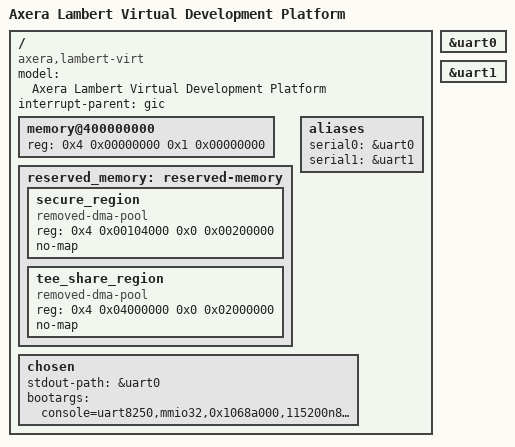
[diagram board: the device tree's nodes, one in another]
// SPDX-License-Identifier: (GPL-2.0+ OR MIT)
/*
 * Copyright (C) 2023 Axera Technology Co., Ltd
 *
 */
/dts-v1/;
#include "axera-lambert.dtsi"

/ {
	compatible = "axera,lambert-virt";
	model = "Axera Lambert Virtual Development Platform";
	#address-cells = <2>;
	#size-cells = <2>;
	interrupt-parent = <&gic>;

	memory@400000000 {
		reg = <0x4 0x00000000 0x1 0x00000000>;
		device_type = "memory";
	};

	reserved_memory: reserved-memory {
		#address-cells = <2>;
		#size-cells = <2>;
		ranges;

		secure_region {
			compatible = "removed-dma-pool";
			reg = <0x4 0x00104000 0x0 0x00200000>;
			no-map;
		};

		tee_share_region {
			compatible = "removed-dma-pool";
			reg = <0x4 0x04000000 0x0 0x02000000>;
			no-map;
		};
	};

	aliases {
		serial0 = &uart0;
		serial1 = &uart1;
	};

	chosen {
		stdout-path = &uart0;
		bootargs = "console=uart8250,mmio32,0x1068a000,115200n8 loglevel=10";
	};
};

&uart0 {
	status = "okay";
};

&uart1 {
	status = "okay";
};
